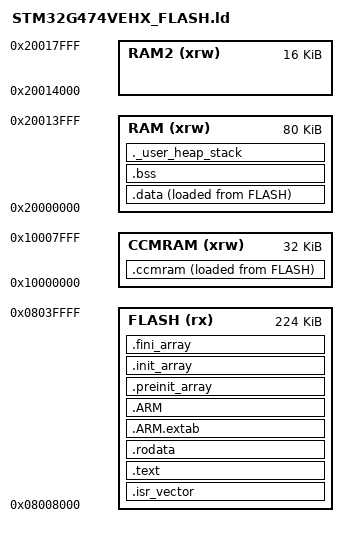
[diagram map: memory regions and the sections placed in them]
/*
******************************************************************************
**
** @file        : LinkerScript.ld
**
** @author      : Auto-generated by STM32CubeIDE
**
** @brief       : Linker script for STM32G474VEHx Device from STM32G4 series
**                      512KBytes FLASH
**                      128KBytes RAM
**
**                Set heap size, stack size and stack location according
**                to application requirements.
**
**                Set memory bank area and size if external memory is used
**
**  Target      : STMicroelectronics STM32
**
**  Distribution: The file is distributed as is, without any warranty
**                of any kind.
**
******************************************************************************
** @attention
**
** Copyright (c) 2026 STMicroelectronics.
** All rights reserved.
**
** This software is licensed under terms that can be found in the LICENSE file
** in the root directory of this software component.
** If no LICENSE file comes with this software, it is provided AS-IS.
**
******************************************************************************
*/

/* Entry Point */
ENTRY(Reset_Handler)

/* Highest address of the user mode stack */
/* Stack lives at the top of RAM2 (SRAM2): its own AHB bus-matrix slave, so the
   per-tick ISR stacking (8 int + 18 lazy FPU words) never arbitrates against DMA
   or .data/.bss traffic in SRAM1. The top 8 bytes (0x20017FF8: "RCSR" magic + value)
   are the bootloader's reset-cause mailbox — keep address in sync with
   bootloader/Src/main.c and the app_main.c read. Nothing else may allocate in RAM2. */
_estack = ORIGIN(RAM2) + LENGTH(RAM2) - 8;

_Min_Heap_Size = 0x400; /* required amount of heap */
_Min_Stack_Size = 0x800; /* required amount of stack */

/* Memories definition.
   FLASH is capped at 224K = the rest of BANK 1 (0x8008000..0x803FFFF; bootloader owns the first
   32K). This is deliberate and load-bearing, not just headroom policing:
     1. Bank 2 holds the persistent calibration page (0x0807F800, bank 2 page 127 — Firmware
        cal_store.{h,c}). With the app image confined to bank 1, dual-bank read-while-write
        guarantees cal_store's erase/program NEVER stall instruction fetch (they run from the
        1 kHz FSM ISR), and no image-extent erase (flash.sh / CubeProgrammer DFU download) can
        ever touch the cal page.
     2. If the app outgrows 224K the build FAILS HERE, forcing a conscious decision (accept
        flash-op stalls + move them out of ISR context, or shrink) instead of silently breaking
        the RWW guarantee. Currently ~95K used — 2.3x headroom.
   MANUAL EDIT on top of the existing 0x8008000 bootloader relink — a CubeMX/CubeIDE regen
   reverts BOTH (see docs/footguns.md). */
MEMORY
{
  CCMRAM (xrw)    : ORIGIN = 0x10000000,   LENGTH = 32K
  RAM    (xrw)    : ORIGIN = 0x20000000,   LENGTH = 80K
  RAM2   (xrw)    : ORIGIN = 0x20014000,   LENGTH = 16K
  FLASH    (rx)    : ORIGIN = 0x8008000,   LENGTH = 224K
}

/* Sections */
SECTIONS
{
  /* The startup code into "FLASH" Rom type memory */
  .isr_vector :
  {
    . = ALIGN(4);
    KEEP(*(.isr_vector)) /* Startup code */
    . = ALIGN(4);
  } >FLASH

  /* Hot-path code/data shadowed into CCM SRAM (0x10000000) at boot. CCM runs with
     zero wait states and no flash-cache jitter — used for the 16 kHz HRTIM fast loop.
     Placed BEFORE .text so the object-file .text pulls below win over the generic
     .text catch-all. LMA in FLASH, VMA in CCMRAM; startup copies it like .data.
     App code lands here via __ccmram (typedefs.h), gated on CCMRAM_HOT_FUNCS. */
  _siccmram = LOADADDR(.ccmram);
  .ccmram :
  {
    . = ALIGN(4);
    _sccmram = .;
    *(.ccmram)
    *(.ccmram*)
    *arm_sin_cos_f32.c.obj(.text .text*)   /* CMSIS-DSP sincos code (vendor, can't annotate) */
    *arm_common_tables.c.obj(.rodata.sinTable_f32 .rodata.sinTable_f32.*)  /* its 513-entry LUT */
    . = ALIGN(4);
    _eccmram = .;
  } >CCMRAM AT> FLASH

  /* The program code and other data into "FLASH" Rom type memory */
  .text :
  {
    . = ALIGN(4);
    *(.text)           /* .text sections (code) */
    *(.text*)          /* .text* sections (code) */
    *(.glue_7)         /* glue arm to thumb code */
    *(.glue_7t)        /* glue thumb to arm code */
    *(.eh_frame)

    KEEP (*(.init))
    KEEP (*(.fini))

    . = ALIGN(4);
    _etext = .;        /* define a global symbols at end of code */
  } >FLASH

  /* Constant data into "FLASH" Rom type memory */
  .rodata :
  {
    . = ALIGN(4);
    *(.rodata)         /* .rodata sections (constants, strings, etc.) */
    *(.rodata*)        /* .rodata* sections (constants, strings, etc.) */
    . = ALIGN(4);
  } >FLASH

  .ARM.extab (READONLY) : /* The "READONLY" keyword is only supported in GCC11 and later, remove it if using GCC10 or earlier. */
  {
    . = ALIGN(4);
    *(.ARM.extab* .gnu.linkonce.armextab.*)
    . = ALIGN(4);
  } >FLASH

  .ARM (READONLY) : /* The "READONLY" keyword is only supported in GCC11 and later, remove it if using GCC10 or earlier. */
  {
    . = ALIGN(4);
    __exidx_start = .;
    *(.ARM.exidx*)
    __exidx_end = .;
    . = ALIGN(4);
  } >FLASH

  .preinit_array (READONLY) : /* The "READONLY" keyword is only supported in GCC11 and later, remove it if using GCC10 or earlier. */
  {
    . = ALIGN(4);
    PROVIDE_HIDDEN (__preinit_array_start = .);
    KEEP (*(.preinit_array*))
    PROVIDE_HIDDEN (__preinit_array_end = .);
    . = ALIGN(4);
  } >FLASH

  .init_array (READONLY) : /* The "READONLY" keyword is only supported in GCC11 and later, remove it if using GCC10 or earlier. */
  {
    . = ALIGN(4);
    PROVIDE_HIDDEN (__init_array_start = .);
    KEEP (*(SORT(.init_array.*)))
    KEEP (*(.init_array*))
    PROVIDE_HIDDEN (__init_array_end = .);
    . = ALIGN(4);
  } >FLASH

  .fini_array (READONLY) : /* The "READONLY" keyword is only supported in GCC11 and later, remove it if using GCC10 or earlier. */
  {
    . = ALIGN(4);
    PROVIDE_HIDDEN (__fini_array_start = .);
    KEEP (*(SORT(.fini_array.*)))
    KEEP (*(.fini_array*))
    PROVIDE_HIDDEN (__fini_array_end = .);
    . = ALIGN(4);
  } >FLASH

  /* Used by the startup to initialize data */
  _sidata = LOADADDR(.data);

  /* Initialized data sections into "RAM" Ram type memory */
  .data :
  {
    . = ALIGN(4);
    _sdata = .;        /* create a global symbol at data start */
    *(.data)           /* .data sections */
    *(.data*)          /* .data* sections */
    *(.RamFunc)        /* .RamFunc sections */
    *(.RamFunc*)       /* .RamFunc* sections */

    . = ALIGN(4);
    _edata = .;        /* define a global symbol at data end */

  } >RAM AT> FLASH

  /* Uninitialized data section into "RAM" Ram type memory */
  . = ALIGN(4);
  .bss :
  {
    /* This is used by the startup in order to initialize the .bss section */
    _sbss = .;         /* define a global symbol at bss start */
    __bss_start__ = _sbss;
    *(.bss)
    *(.bss*)
    *(COMMON)

    . = ALIGN(4);
    _ebss = .;         /* define a global symbol at bss end */
    __bss_end__ = _ebss;
  } >RAM

  /* Heap reservation/overflow check. The stack no longer counts against RAM: it
     lives in RAM2 (see _estack above), where it has ~16 KB to itself. */
  ._user_heap_stack :
  {
    . = ALIGN(8);
    PROVIDE ( end = . );
    PROVIDE ( _end = . );
    . = . + _Min_Heap_Size;
    . = ALIGN(8);
  } >RAM

  /* Remove information from the compiler libraries */
  /DISCARD/ :
  {
    libc.a ( * )
    libm.a ( * )
    libgcc.a ( * )
  }

  .ARM.attributes 0 : { *(.ARM.attributes) }
}
